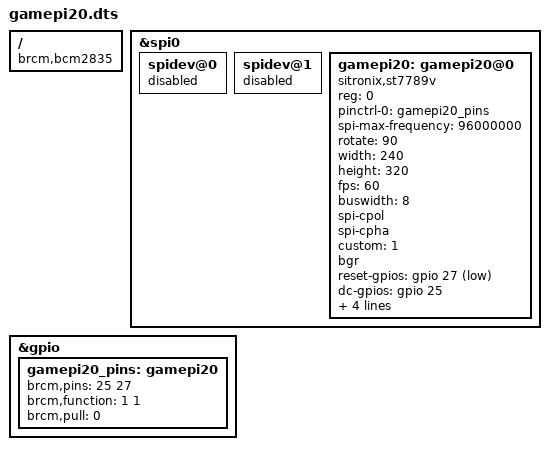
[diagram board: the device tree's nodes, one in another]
/dts-v1/;
/plugin/;

/ {
        compatible = "brcm,bcm2835", "brcm,bcm2708", "brcm,bcm2709";

        fragment@0 {
                target = <&spi0>;
                __overlay__ {
                        status = "okay";

                        spidev@0{
                                status = "disabled";
                        };

                        spidev@1{
                                status = "disabled";
                        };
                };
        };

        fragment@1 {
                target = <&gpio>;
                __overlay__ {
                        gamepi20_pins: gamepi20 {
                                brcm,pins = <25 27 >;
                                brcm,function = <1 1>; /* out */
                                brcm,pull = <0>; /* none */
                        };
                };
        };

        fragment@2 {
                target = <&spi0>;
                __overlay__ {
                        /* needed to avoid dtc warning */
                        #address-cells = <1>;
                        #size-cells = <0>;

                        gamepi20: gamepi20@0{
                		compatible = "sitronix,st7789v";
                                reg = <0>;
                                pinctrl-names = "default";
                                pinctrl-0 = <&gamepi20_pins>;
                                
								spi-max-frequency = <96000000>;
                                
								rotate = <90>;
                                width = <240>;
                                height = <320>;
								fps = <60>;
                                buswidth = <8>;
								spi-cpol;
                                spi-cpha;
								custom = <1>;
								bgr;
								
                                reset-gpios = <&gpio 27 1>;
								dc-gpios = <&gpio 25 0>;
                                led-gpios = <&gpio 24 0>;
								/*cs-gpios = <&gpio 8 0>;*/
								
                                debug = <0>;
					
								init = <0x1000011
										0x20000ff
										0x1000036 0xA0
										0x100003a 0x05
										0x1000021 
										0x100002a 0x00 0x01 0x00 0x3f
										0x100002b 0x00 0x00 0x00 0xef
										0x10000b2 0x0c 0x0c 0x00 0x33 0x33
										0x10000b7 0x35
										0x10000bb 0x1f
										0x10000c0 0x0c
										0x10000c2 0x01
										0x10000c3 0x12
										0x10000c4 0x20
										0x10000c6 0x0f
										0x10000d0 0xa4 0xa1
										0x10000e0 0xd0 0x08 0x11 0x08 0x0C 0x15 0x39 0x33 0x50 0x36 0x13 0x14 0x29 0x2d
										0x10000e1 0xd0 0x08 0x10 0x08 0x06 0x06 0x39 0x44 0x51 0x0b 0x16 0x14 0x2f 0x31
										0x1000029>;
                        };
                };
        };


        __overrides__ {
                speed =   <&gamepi20>,"spi-max-frequency:0";
                rotate =  <&gamepi20>,"rotate:0";
                width =   <&gamepi20>,"width:0";
                height =  <&gamepi20>,"height:0";
                fps =     <&gamepi20>,"fps:0";
                debug =   <&gamepi20>,"debug:0";
        };
};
